VERSION ""

NS_ :

BS_:

BU_: BigBMS Converter CoolingBack CoolingLeft CoolingMotor CoolingRight Dashboard Engines JETSON LightsFR LightsFL LightsRR LightsRL MPPT Pedals RCD SafeState SensorFR SensorFL SensorRR SensorRL SmallBMS

BO_ 1952 LightsRL_NODE: 8 LightsRL

BO_ 1920 LightsRR_NODE: 8 LightsRR

BO_ 1888 LightsFL_NODE: 8 LightsFL

BO_ 1856 LightsFR_NODE: 8 LightsFR

BO_ 1696 SensorRL_NODE: 8 SensorRL

BO_ 1664 SensorRR_NODE: 8 SensorRR

BO_ 1632 SensorFL_NODE: 8 SensorFL

BO_ 1600 SensorFR_NODE: 8 SensorFR

BO_ 1472 LowVoltConverter_NODE: 8 Converter

BO_ 1344 CoolingMotor_NODE: 8 CoolingMotor

BO_ 1312 CoolingRight_NODE: 8 CoolingRight

BO_ 1280 CoolingLeft_NODE: 8 CoolingLeft

BO_ 1248 CoolingBack_NODE: 8 CoolingBack

BO_ 1120 MPPT_NODE: 8 MPPT

BO_ 992 Dashboard_NODE: 8 Dashboard

BO_ 864 SmallBMS_NODE: 8 SmallBMS

BO_ 192 RCD_STATIC_NODE: 8 RCD

BO_ 128 BigBMS_NODE: 8 BigBMS

BO_ 64 Pedals_NODE: 8 Pedals

BO_ 512 JETSON_STATIC_NODE: 8 JETSON

BO_ 0 SafeState_NODE: 8 SafeState

BO_ 416 Engines1_STATIC_NODE: 8 Engines

BO_ 672 Engines2_STATIC_NODE: 8 Engines

BO_ 1824 Engines3_STATIC_NODE: 8 Engines

BO_ 1983 LightsRL_END: 8 LightsRL

BO_ 1727 SensorRL_END: 8 SensorRL

BO_ 1951 LightsRR_END: 8 LightsRR

BO_ 31 SafeState_END: 8 SafeState

BO_ 95 Pedals_END: 8 Pedals

BO_ 159 BigBMS_END: 8 BigBMS

BO_ 223 RCD_STATIC_END: 8 RCD

BO_ 543 JETSON_STATIC_END: 8 JETSON

BO_ 895 SmallBMS_END: 8 SmallBMS

BO_ 1503 LowVoltConverter_END: 8 Converter

BO_ 1279 CoolingBack_END: 8 CoolingBack

BO_ 1311 CoolingLeft_END: 8 CoolingLeft

BO_ 1375 CoolingMotor_END: 8 CoolingMotor

BO_ 1343 CoolingRight_END: 8 CoolingRight

BO_ 1023 Dashboard_END: 8 Dashboard

BO_ 1151 MPPT_END: 8 MPPT

BO_ 1653 SensorFL_END: 8 SensorFL

BO_ 1631 SensorFR_END: 8 SensorFR

BO_ 1695 SensorRR_END: 8 SensorRR

BO_ 1919 LightsFL_END: 8 LightsFL

BO_ 1887 LightsFR_END: 8 LightsFR

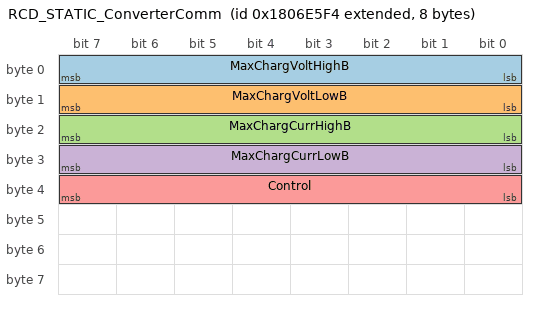
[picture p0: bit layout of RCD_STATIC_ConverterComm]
BO_ 2550588916 RCD_STATIC_ConverterComm: 8 RCD
 SG_ MaxChargVoltHighB : 0|8@1+ (1,0) [0|0] "V" Vector__XXX
 SG_ MaxChargVoltLowB : 8|8@1+ (1,0) [0|0] "V" Vector__XXX
 SG_ MaxChargCurrHighB : 16|8@1+ (1,0) [0|0] "A" Vector__XXX
 SG_ MaxChargCurrLowB : 24|8@1+ (1,0) [0|0] "A" Vector__XXX
 SG_ Control : 32|8@1+ (1,0) [0|0] "" Vector__XXX

BO_ 3221225472 VECTOR__INDEPENDENT_SIG_MSG: 0 Vector__XXX
 SG_ Error_Code : 0|16@1+ (1,0) [0|0] "" Vector__XXX
 SG_ Node_Execution_Halted : 23|1@1+ (1,0) [0|0] "" Vector__XXX
 SG_ Severity : 20|3@1+ (1,0) [0|0] "" Vector__XXX
 SG_ Reserved : 16|4@1+ (1,0) [0|0] "" Vector__XXX
 SG_ Error_Specific_Data : 24|40@1+ (1,0) [0|0] "" Vector__XXX

CM_ BO_ 0 "
";
CM_ SG_ 3221225472 Error_Code "Error code from csv errors file
";
CM_ SG_ 3221225472 Reserved "Reserved for future use";
CM_ SG_ 3221225472 Error_Specific_Data "Blob for error specific data (sensor reading, variable dump, etc. - depeneds of error)";
VAL_ 2550588916 Control 1 "Start charging" 0 "Stop charging" ;
VAL_ 3221225472 Node_Execution_Halted 0 "Running" 1 "Halted" ;
VAL_ 3221225472 Severity 1 "Error" 2 "Warning" 3 "Info" ;
